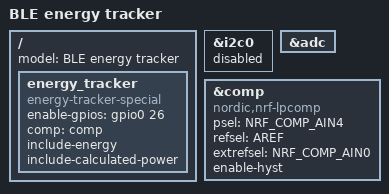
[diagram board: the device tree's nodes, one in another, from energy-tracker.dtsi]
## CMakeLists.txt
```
cmake_minimum_required(VERSION 3.13.1)
find_package(Zephyr REQUIRED HINTS $ENV{ZEPHYR_BASE})

project(app LANGUAGES C)

target_sources(app PRIVATE src/main.c src/environment-sensors.c)
```

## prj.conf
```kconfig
CONFIG_BOOT_BANNER_STRING="BLE Door Sensor - build"

# enable GPIO
CONFIG_GPIO=y

# enable ADC
CONFIG_ADC=y

# enable power management
CONFIG_PM_DEVICE=y
CONFIG_PM_DEVICE_RUNTIME=y

#enable Bluetooth
CONFIG_BT=y
CONFIG_BT_PERIPHERAL=y
CONFIG_BT_DEVICE_NAME="Sensor"

# Maybe replace with my own private key?
CONFIG_MCUBOOT_SIGNATURE_KEY_FILE="bootloader/mcuboot/root-ec-p256.pem"

# Enable MCUmgr and dependencies.
CONFIG_NET_BUF=y
CONFIG_ZCBOR=y
CONFIG_CRC=y
CONFIG_MCUMGR=y
CONFIG_STREAM_FLASH=y
CONFIG_FLASH_MAP=y

# Some command handlers require a large stack.
CONFIG_SYSTEM_WORKQUEUE_STACK_SIZE=2304
CONFIG_MAIN_STACK_SIZE=2048

# Ensure an MCUboot-compatible binary is generated.
CONFIG_BOOTLOADER_MCUBOOT=y

# Enable flash operations.
CONFIG_FLASH=y

# Enable most core commands.
CONFIG_FLASH=y
CONFIG_IMG_MANAGER=y
CONFIG_MCUMGR_GRP_IMG=y
CONFIG_MCUMGR_GRP_OS=y

# Allow for large Bluetooth data packets.
CONFIG_BT_L2CAP_TX_MTU=498
CONFIG_BT_BUF_ACL_RX_SIZE=502
CONFIG_BT_BUF_ACL_TX_SIZE=502
CONFIG_BT_CTLR_DATA_LENGTH_MAX=251

# Enable the Bluetooth mcumgr transport (unauthenticated).
CONFIG_MCUMGR_TRANSPORT_BT=y
CONFIG_MCUMGR_TRANSPORT_BT_PERM_RW=y
CONFIG_MCUMGR_TRANSPORT_BT_CONN_PARAM_CONTROL=y


# Enable the mcumgr Packet Reassembly feature over Bluetooth and its configuration dependencies.
# MCUmgr buffer size is optimized to fit one SMP packet divided into five Bluetooth Write Commands,
# transmitted with the maximum possible MTU value: 498 bytes.
CONFIG_MCUMGR_TRANSPORT_BT_REASSEMBLY=y
CONFIG_MCUMGR_TRANSPORT_NETBUF_SIZE=2475
CONFIG_MCUMGR_GRP_OS_MCUMGR_PARAMS=y
CONFIG_MCUMGR_TRANSPORT_WORKQUEUE_STACK_SIZE=4608

# Disable Bluetooth ping support
CONFIG_BT_CTLR_LE_PING=n

# Disable shell commands that are not needed
CONFIG_CLOCK_CONTROL_NRF_SHELL=n
CONFIG_DEVICE_SHELL=n
CONFIG_DEVMEM_SHELL=n
CONFIG_FLASH_SHELL=n

# Disable Bluetooth PHY update support
CONFIG_BT_USER_PHY_UPDATE=n
CONFIG_BT_PHY_UPDATE=n

CONFIG_BTHOME=y
```

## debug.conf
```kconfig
# compiler
CONFIG_DEBUG_OPTIMIZATIONS=y

# console
CONFIG_CONSOLE=y

# UART console
CONFIG_SERIAL=y
CONFIG_UART_CONSOLE=y

# logging
CONFIG_LOG=y
CONFIG_APP_LOG_LEVEL_DBG=y
```

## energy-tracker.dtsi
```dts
#include <zephyr/dt-bindings/comparator/nrf-comp.h>

/ {
	model = "BLE energy tracker";

	/delete-node/ ambient_light_sensor;
	/delete-node/ temp_humidity;
	/delete-node/ window;
	/delete-node/ button;

	energy_tracker {
		compatible = "energy-tracker-special";
		enable-gpios = <&gpio0 26 GPIO_ACTIVE_HIGH>;
		comp = <&comp>;
		include-energy;
		include-calculated-power;
	};
};

&i2c0 {
	status = "disabled";
	/delete-node/ shtc3@70;
};

&adc {
	/delete-node/ channel@4;
};

&comp {
	compatible = "nordic,nrf-lpcomp";
	status = "okay";
	psel = <NRF_COMP_AIN4>;
	refsel = "AREF";
	extrefsel = <NRF_COMP_AIN0>;
	enable-hyst;
};
```

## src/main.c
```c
#include <zephyr/kernel.h>
#include <zephyr/drivers/gpio.h>

#include <zephyr/sys/reboot.h>
#include <zephyr/logging/log_ctrl.h>

#include <zephyr/logging/log.h>
LOG_MODULE_REGISTER(main, CONFIG_APP_LOG_LEVEL);

static const struct gpio_dt_spec led = GPIO_DT_SPEC_GET(DT_ALIAS(led0), gpios);

void k_sys_fatal_error_handler(unsigned int reason, const struct arch_esf *esf)
{
	ARG_UNUSED(esf);

	LOG_PANIC();
	LOG_ERR("Rebooting system");

	sys_reboot(SYS_REBOOT_COLD);

	CODE_UNREACHABLE; /* LCOV_EXCL_LINE */
}

int main(void)
{
	printk("Starting BLE Door Sensor\n");

	// short blink to signal everything is okay
	for(int i = 0; i <3; i++) {
		gpio_pin_set_dt(&led, 1);
		k_msleep(80);
		gpio_pin_set_dt(&led, 0);
		k_msleep(100);
	}

	return 0;
}
```

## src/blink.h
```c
/*
 * Copyright (c) 2024 Nordic Semiconductor ASA
 * SPDX-License-Identifier: Apache-2.0
 */

#ifndef APP_DRIVERS_BLINK_H_
#define APP_DRIVERS_BLINK_H_

#include <zephyr/device.h>
#include <zephyr/toolchain.h>

struct bt_data;

int energy_init(const struct device *dev,
				struct bt_data *bt_data, size_t data_size, uint32_t *energy_wh);

#endif /* APP_DRIVERS_BLINK_H_ */
```

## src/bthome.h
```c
#ifndef BT_HOME_H
#define BT_HOME_H

#define BTHOME_INFO_VERSION            0x40
#define BTHOME_INFO_REGULAR_INTERVAL   0x00
#define BTHOME_INFO_IRREGULAR_INTERVAL 0x04
#define BTHOME_INFO_ENCRYPTED_DATA     0x01
#define BTHOME_INFO_UNENCRYPTED_DATA   0x00

#define BTHOME_SENSOR_BATTERY        0x01
#define BTHOME_SENSOR_TEMPERATURE    0x02
#define BTHOME_SENSOR_HUMIDITY_16    0x03
#define BTHOME_SENSOR_ILLUMINANCE    0x05
#define BTHOME_SENSOR_BINARY_BATTERY 0x15
#define BTHOME_SENSOR_BINARY_DOOR    0x1A
#define BTHOME_SENSOR_BINARY_WINDOW  0x2D
#define BTHOME_SENSOR_HUMIDITY_8     0x2E
#define BTHOME_SENSOR_BUTTON         0x3A
#define BTHOME_SENSOR_ENERGY_WH      0x4D
#define BTHOME_SENSOR_POWER_10MW_24BIT 0x0B

#define BTHOME_VALUE_DOOR_CLOSED         0x00
#define BTHOME_VALUE_DOOR_OPEN           0x01
#define BTHOME_VALUE_BUTTON_NONE         0x00
#define BTHOME_VALUE_BUTTON_PRESSED      0x01
#define BTHOME_VALUE_BUTTON_DOUBLE_PRESS 0x02
#define BTHOME_VALUE_BUTTON_TRIPLE_PRESS 0x03
#define BTHOME_VALUE_BUTTON_LONG_PRESS   0x04
#define BTHOME_VALUE_WINDOW_CLOSED       0x00
#define BTHOME_VALUE_WINDOW_OPEN         0x01
#define BTHOME_VALUE_BATTERY_ERROR       0xFF // just a first guess from my side. Need to verify

#define BTHOME_SERVICE_UUID 0xfcd2

#endif /* BT_HOME_H */
```

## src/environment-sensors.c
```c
#include "environment-sensors.h"
#include "bthome.h"

#include <zephyr/drivers/adc.h>
#include <zephyr/drivers/gpio.h>
#include <zephyr/drivers/sensor.h>

#include <zephyr/bluetooth/bluetooth.h>

#include <zephyr/logging/log.h>
LOG_MODULE_REGISTER(environment_sensors, CONFIG_APP_LOG_LEVEL);

static const struct adc_dt_spec soc_voltage = ADC_DT_SPEC_GET_BY_IDX(DT_PATH(zephyr_user), 0);

static struct battery_reading {
	struct bt_data *data;
	size_t data_size;
	uint8_t *battery;
	struct k_work_delayable work;
} reading_g;

static void read_supply_voltage(uint8_t *battery)
{
	static int adc_read_error_counter = 0;
	uint16_t buf;
	struct adc_sequence sequence = {
		.buffer = &buf,
		/* buffer size in bytes, not number of samples */
		.buffer_size = sizeof(buf),
	};
	(void)adc_sequence_init_dt(&soc_voltage, &sequence);

	int err = adc_read_dt(&soc_voltage, &sequence);
	if (err < 0) {
		printk("Could not read ADC (%d)\n", err);
		adc_read_error_counter++;
		if (adc_read_error_counter > 10) {
			*battery = BTHOME_VALUE_BATTERY_ERROR;
		}
		return;
	}
	adc_read_error_counter = 0;
	int32_t batt = (int32_t)buf;
	adc_raw_to_millivolts_dt(&soc_voltage, &batt);
	// convert mv to percentage with 3V beeing 100% and 2V beeing 0%
	// This is not a battery curve, just some calculations for better or worse.
	batt -= 2000;
	batt /= 10;
	if (batt > 100) {
		batt = 100;
	} else if (batt < 0) {
		batt = 0;
	}
	LOG_DBG("Battery is at %d percent", batt);
	*battery = (uint8_t)batt;
}

static void read_sensors_cb(struct k_work *_work)
{
	struct k_work_delayable *work = k_work_delayable_from_work(_work);
	k_work_reschedule(work, K_MINUTES(10));
	struct battery_reading *reading = CONTAINER_OF(work, struct battery_reading, work);

	uint8_t battery;
	read_supply_voltage(&battery);

	if (battery == *reading->battery) {
		return;
	}

	LOG_INF("Battery changed from %d to %d", *reading->battery, battery);
	*reading->battery = battery;

	int ret = bt_le_adv_update_data(reading->data, reading->data_size, NULL, 0);
	if (ret) {
		LOG_ERR("Failed to update advertising data (err %d)", ret);
	}
}

int battery_init(struct bt_data *data, size_t data_size, uint8_t *battery)
{
	reading_g.data = data;
	reading_g.data_size = data_size;
	reading_g.battery = battery;
	reading_g.work.work.handler = read_sensors_cb;
	reading_g.work.work.flags = K_WORK_DELAYABLE;

	if (!adc_is_ready_dt(&soc_voltage)) {
		printk("ADC controller device %s not ready\n", soc_voltage.dev->name);
		return -EBADFD;
	}

	int ret = adc_channel_setup_dt(&soc_voltage);
	if (ret < 0) {
		printk("Could not setup adc (%d)\n", ret);
		return ret;
	}

	k_work_schedule(&reading_g.work, K_MINUTES(10));

	return 0;
}
```

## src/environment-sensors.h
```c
#ifndef ENVIRONMENT_SENSORS_H
#define ENVIRONMENT_SENSORS_H

#include <zephyr/kernel.h>
#include <zephyr/bluetooth/bluetooth.h>

int battery_init(struct bt_data *data, size_t data_size, uint8_t *battery);

#endif /* ENVIRONMENT_SENSORS_H */
```

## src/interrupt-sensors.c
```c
#include "interrupt-sensors.h"

#include "bthome.h"

#include <zephyr/drivers/gpio.h>

#include <zephyr/logging/log.h>
LOG_MODULE_REGISTER(interrupt_sensors, CONFIG_APP_LOG_LEVEL);

static const struct gpio_dt_spec hall_sensor = GPIO_DT_SPEC_GET(DT_NODELABEL(hall_sensor), gpios);
static const struct gpio_dt_spec button = GPIO_DT_SPEC_GET(DT_NODELABEL(button), gpios);
static struct gpio_callback hall_sensor_callback;
static struct gpio_callback button_callback;
static struct k_work_delayable *read_sensors_work;

static uint8_t button_value = BTHOME_VALUE_BUTTON_NONE;

static int64_t time_last_button_action;

static void stop_button_cb(struct k_work *_work)
{
	LOG_DBG("Stopping button press.");
	// we have broadcasted our button press long enough.
	button_value = BTHOME_VALUE_BUTTON_NONE;
	k_work_reschedule(read_sensors_work, K_NO_WAIT);
}
K_WORK_DELAYABLE_DEFINE(stop_button_work, stop_button_cb);

static void button_cb(struct k_work *_work)
{
	int64_t difference = sys_clock_tick_get() - time_last_button_action;
	LOG_DBG("Time difference: %lld", difference);

	if (difference >= k_ms_to_ticks_ceil32(4000)) {
		button_value = BTHOME_VALUE_BUTTON_LONG_PRESS;
		LOG_DBG("Sending long press");
	} else {
		button_value = BTHOME_VALUE_BUTTON_PRESSED;
		LOG_DBG("Sending short press");
	}

	// stop the current button symbol in 5 minutes
	k_work_reschedule(&stop_button_work, K_MINUTES(6));
	// but start broadcasting the current button symbol now
	k_work_reschedule(read_sensors_work, K_NO_WAIT);
}
K_WORK_DELAYABLE_DEFINE(button_work, button_cb);

static void button_pressed(const struct device *dev, struct gpio_callback *cb, uint32_t pins)
{
	ARG_UNUSED(cb);
	int state = gpio_pin_get_dt(&button);
	LOG_DBG("Button interrupt with value %d", state);
	switch (state) {
	case 1:
		time_last_button_action = sys_clock_tick_get();
		// 4 seconds is long enough for long button press.
		k_work_reschedule(&button_work, K_SECONDS(4));
		return;
	case 0:
		int64_t difference = sys_clock_tick_get() - time_last_button_action;
		if (difference < k_ms_to_ticks_ceil32(4000)) {
			// if it is after 4 seconds, then we have already send a long press.
			k_work_reschedule(&button_work, K_NO_WAIT);
		}
		return;

	default:
		break;
	}
	if (state < 0) {
		return;
	}
}

static void hall_sensor_triggered(const struct device *dev, struct gpio_callback *cb, uint32_t pins)
{
	ARG_UNUSED(dev);
	ARG_UNUSED(cb);
	ARG_UNUSED(pins);
	// delay by a bit to account for bouncing effects.
	k_work_reschedule(read_sensors_work, Z_TIMEOUT_MS(100));
}

static int configure_interrupt_gpio(const struct gpio_dt_spec *hall_sensor)
{
	int ret;
	if (!gpio_is_ready_dt(hall_sensor)) {
		LOG_ERR("Error: Sensor device %s is not ready", hall_sensor->port->name);
		return -EBADFD;
	}

	ret = gpio_pin_configure_dt(hall_sensor, GPIO_INPUT);
	if (ret != 0) {
		LOG_ERR("Error %d: failed to configure %s pin %d", ret, hall_sensor->port->name,
			hall_sensor->pin);
		return ret;
	}

	ret = gpio_pin_interrupt_configure_dt(hall_sensor, GPIO_INT_EDGE_BOTH);
	if (ret != 0) {
		LOG_ERR("Error %d: failed to configure interrupt on %s pin %d", ret,
			hall_sensor->port->name, hall_sensor->pin);
		return ret;
	}

	LOG_DBG("Set up gpio at %s pin %d", hall_sensor->port->name, hall_sensor->pin);
	return 0;
}

int int_init_sensors(struct k_work_delayable *sensors_read)
{
	read_sensors_work = sensors_read;

	int ret;

	ret = configure_interrupt_gpio(&hall_sensor);
	if (ret < 0) {
		return ret;
	}
	gpio_init_callback(&hall_sensor_callback, hall_sensor_triggered, BIT(hall_sensor.pin));
	gpio_add_callback(hall_sensor.port, &hall_sensor_callback);

	ret = configure_interrupt_gpio(&button);
	if (ret < 0) {
		return ret;
	}

	gpio_init_callback(&button_callback, button_pressed, BIT(button.pin));
	gpio_add_callback(button.port, &button_callback);

	time_last_button_action = sys_clock_tick_get();

	return ret;
}

int int_read_sensor_data(uint8_t *button_val, uint8_t *window)
{
	int ret = 0;
	switch (gpio_pin_get_dt(&hall_sensor)) {
	case 0:
		*window = BTHOME_VALUE_WINDOW_OPEN;
		break;
	case 1:
		*window = BTHOME_VALUE_WINDOW_CLOSED;
		break;
	default:
		ret = -EIO;
		break;
	}
	*button_val = button_value;
	LOG_DBG("Window: %s Button: %s", *window ? "open" : "closed",
		*button_val ? "pressed" : "idle");
	return 0;
}
```

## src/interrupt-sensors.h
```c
#ifndef INTERRUPT_SENSORS_H
#define INTERRUPT_SENSORS_H

#include <zephyr/kernel.h>

int int_init_sensors(struct k_work_delayable *read_sensors_work);

int int_read_sensor_data(uint8_t *button, uint8_t *window);

#endif /* INTERRUPT_SENSORS_H */
```

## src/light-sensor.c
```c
/*
 * Copyright (c) 2023 Google LLC
 * Copyright (c) 2024 Fabian Pflug
 *
 * SPDX-License-Identifier: Apache-2.0
 *
 * Based upon the NTC-Thermistor code
 */

#include <zephyr/kernel.h>
#include <zephyr/drivers/adc.h>
#include <zephyr/drivers/gpio.h>
#include <zephyr/drivers/sensor.h>

#include <zephyr/bluetooth/bluetooth.h>

#include "blink.h"

#include <zephyr/logging/log.h>
#define DT_DRV_COMPAT phototransistor_special

LOG_MODULE_REGISTER(phototransistor, CONFIG_SENSOR_LOG_LEVEL);

struct phototransistor_data {
	struct bt_data *data;
	size_t data_size;
	uint32_t *energy_wh;
	uint32_t last_reading;
	struct k_work_delayable work;
	const struct device *dev;
	int num_below_threshold;
};

struct phototransistor_config {
	const struct adc_dt_spec adc_channel;
	struct gpio_dt_spec enable;
	uint32_t pulldown_ohm;
};

static int phototransistor_sample_fetch(const struct device *dev, uint32_t *val_mv)
{
	const struct phototransistor_config *cfg = dev->config;
	uint32_t raw_val;
	int res;
	struct adc_sequence sequence = {
		.options = NULL,
		.buffer = &raw_val,
		.buffer_size = sizeof(raw_val),
		.calibrate = false,
	};

	int err = gpio_pin_set_dt(&cfg->enable, 1);
	if (err != 0) {
		LOG_ERR("Could not set enable pin!");
		return -EIO;
	}

	// Wait for output voltage to stabilize
	k_sleep(K_USEC(150));

	adc_sequence_init_dt(&cfg->adc_channel, &sequence);
	res = adc_read(cfg->adc_channel.dev, &sequence);
	if (!res) {
		*val_mv = raw_val;
		// If the number is 16 bit signed negative, then there is an error.
		// Especially since we have less then 15 bit resolution.
		if (raw_val & 0x8000) {
			*val_mv = 0;
		} else {
			res = adc_raw_to_millivolts_dt(&cfg->adc_channel, val_mv);
		}
		LOG_DBG("Measured: %d -> %d mV", raw_val, *val_mv);
	}

	gpio_pin_set_dt(&cfg->enable, 0);

	return res;
}

static void read_sensors_cb(struct k_work *_work)
{
	struct k_work_delayable *work = k_work_delayable_from_work(_work);
	k_work_reschedule(work, K_MSEC(30));
	struct phototransistor_data *data = CONTAINER_OF(work, struct phototransistor_data, work);

	uint32_t raw_mv = 0;
	int ret = phototransistor_sample_fetch(data->dev, &raw_mv);
	if (ret) {
		LOG_ERR("Could not read phototransistor (%d)", ret);
		return;
	}

	// It roughly toggles between 0 and 100mV, but I have seen 80 to 130 mV.
	if (raw_mv < 40) {
		data->num_below_threshold++;
	} else {
		data->num_below_threshold = 0;
	}

	if (data->num_below_threshold != 2) {
		return;
	}

	(*data->energy_wh)++;

	LOG_INF("Energy is now %d Wh", *data->energy_wh);

	ret = bt_le_adv_update_data(data->data, data->data_size, NULL, 0);
	if (ret) {
		LOG_ERR("Failed to update advertising data (err %d)", ret);
	}
}

int energy_init(const struct device *dev, struct bt_data *bt_data, size_t data_size,
		uint32_t *energy_wh)
{

	struct phototransistor_data *data = dev->data;
	data->data = bt_data;
	data->data_size = data_size;
	data->energy_wh = energy_wh;

	k_work_reschedule(&data->work, K_MSEC(30));
	return 0;
}

static int phototransistor_init(const struct device *dev)
{
	const struct phototransistor_config *cfg = dev->config;
	int err;

	if (!gpio_is_ready_dt(&cfg->enable)) {
		LOG_ERR("GPIO port %s is not ready", cfg->enable.port->name);
		return -ENODEV;
	}

	err = gpio_pin_configure_dt(&cfg->enable, GPIO_OUTPUT_INACTIVE);
	if (err < 0) {
		LOG_ERR("Could not configure enable pin!");
		return err;
	}

	if (!adc_is_ready_dt(&cfg->adc_channel)) {
		LOG_ERR("ADC controller device is not ready\n");
		return -ENODEV;
	}

	err = adc_channel_setup_dt(&cfg->adc_channel);
	if (err < 0) {
		LOG_ERR("Could not setup channel err(%d)\n", err);
		return err;
	}

	struct phototransistor_data *data = dev->data;
	data->dev = dev;

	return 0;
}

#define PHOTOTRANSISTOR_DEFINE(inst)                                                               \
	static struct phototransistor_data phototransistor_driver_##inst = {                       \
		.work = Z_WORK_DELAYABLE_INITIALIZER(read_sensors_cb),                             \
		.num_below_threshold = 0,                                                          \
	};                                                                                         \
                                                                                                   \
	static const struct phototransistor_config phototransistor_cfg_##inst = {                  \
		.adc_channel = ADC_DT_SPEC_INST_GET(inst),                                         \
		.enable = GPIO_DT_SPEC_INST_GET(inst, enable_gpios),                               \
		.pulldown_ohm = DT_INST_PROP(inst, pulldown_ohm),                                  \
	};                                                                                         \
                                                                                                   \
	DEVICE_DT_INST_DEFINE(inst, phototransistor_init, NULL, &phototransistor_driver_##inst,    \
			      &phototransistor_cfg_##inst, POST_KERNEL,                            \
			      CONFIG_SENSOR_INIT_PRIORITY, NULL);

DT_INST_FOREACH_STATUS_OKAY(PHOTOTRANSISTOR_DEFINE)
```
